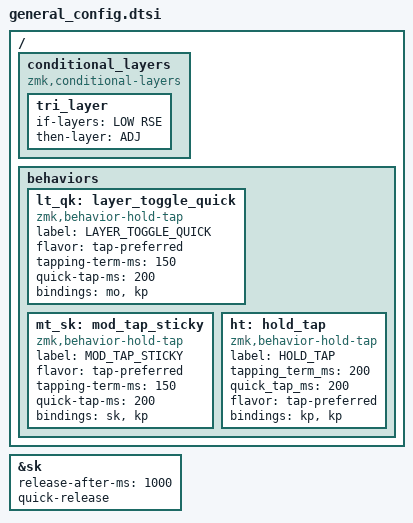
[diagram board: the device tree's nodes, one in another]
#include <behaviors.dtsi>
#include <dt-bindings/zmk/keys.h>
#include <dt-bindings/zmk/bt.h>
#include <dt-bindings/zmk/rgb.h>
#include <dt-bindings/zmk/ext_power.h>
#include <dt-bindings/zmk/outputs.h>

#define DEF 0
#define LOW 1
#define RSE 2
#define ADJ 3

&sk {
  release-after-ms = <1000>;
  quick-release;
};



/ {
    conditional_layers {
      compatible = "zmk,conditional-layers";

      tri_layer {
          if-layers = <LOW RSE>;
          then-layer = <ADJ>;
      };
    };

  behaviors {
    lt_qk: layer_toggle_quick {
        compatible = "zmk,behavior-hold-tap";
        label = "LAYER_TOGGLE_QUICK";
        #binding-cells = <2>;
        flavor = "tap-preferred";
        tapping-term-ms = <150>;
        quick-tap-ms = <200>;
        bindings = <&mo>, <&kp>;
    };
    mt_sk: mod_tap_sticky {
      compatible = "zmk,behavior-hold-tap";
      label = "MOD_TAP_STICKY";
      #binding-cells = <2>;
      flavor = "tap-preferred";
      tapping-term-ms = <150>;
      quick-tap-ms = <200>;
      bindings = <&sk>, <&kp>;
    };
    ht: hold_tap {
        compatible = "zmk,behavior-hold-tap";
        label = "HOLD_TAP";
        #binding-cells = <2>;
        tapping_term_ms = <200>;
        quick_tap_ms = <200>;
        flavor = "tap-preferred";
        bindings = <&kp>, <&kp>;
    };
  };
};


